# CPSW_CPSW_52800000h register map
Vendor: Texas Instruments
Registers are 32-bit, read-write, reset 0x0 unless marked. A register's access mark holds for its fields unless they carry their own. Offsets are as the file gives them; [hi:lo] are bit positions; {n}, {i} and the like mark numbered series; 'fields as' and 'values as' point back to an identical list.

## CPSW (part 3 of 4)
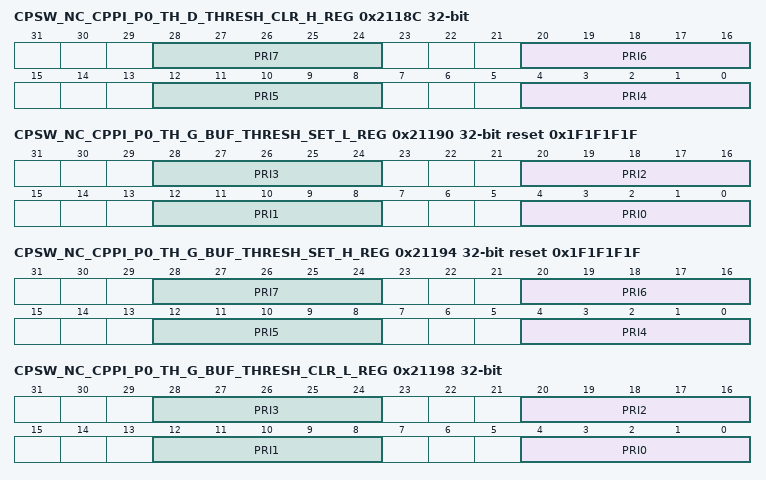
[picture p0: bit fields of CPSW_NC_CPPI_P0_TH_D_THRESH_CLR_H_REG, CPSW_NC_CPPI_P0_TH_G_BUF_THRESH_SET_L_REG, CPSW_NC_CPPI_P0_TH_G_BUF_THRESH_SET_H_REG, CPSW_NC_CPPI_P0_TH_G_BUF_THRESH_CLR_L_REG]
0x2118C CPSW_NC_CPPI_P0_TH_D_THRESH_CLR_H_REG — CPPI Port 0 Tx PFC Destination Threshold Clr High
  [8n-28:8n-32] PRI{n} (n=4..7) — Port Priority Based Flow Control Threshold Clear Value for Priority {n}
0x21190 CPSW_NC_CPPI_P0_TH_G_BUF_THRESH_SET_L_REG reset 0x1F1F1F1F — CPPI Port 0 Tx PFC Global Buffer Threshold Set Low
  [8n+4:8n] PRI{n} (n=0..3) — Port Priority Based Flow Control Threshold Set Value for Priority {n}
0x21194 CPSW_NC_CPPI_P0_TH_G_BUF_THRESH_SET_H_REG reset 0x1F1F1F1F — CPPI Port 0 Tx PFC Global Buffer Threshold Set High
  [8n-28:8n-32] PRI{n} (n=4..7) — Port Priority Based Flow Control Threshold Set Value for Priority {n}
0x21198 CPSW_NC_CPPI_P0_TH_G_BUF_THRESH_CLR_L_REG — CPPI Port 0 Tx PFC Global Buffer Threshold Clr Low
  [8n+4:8n] PRI{n} (n=0..3) — Port Priority Based Flow Control Threshold Clear Value for Priority {n}
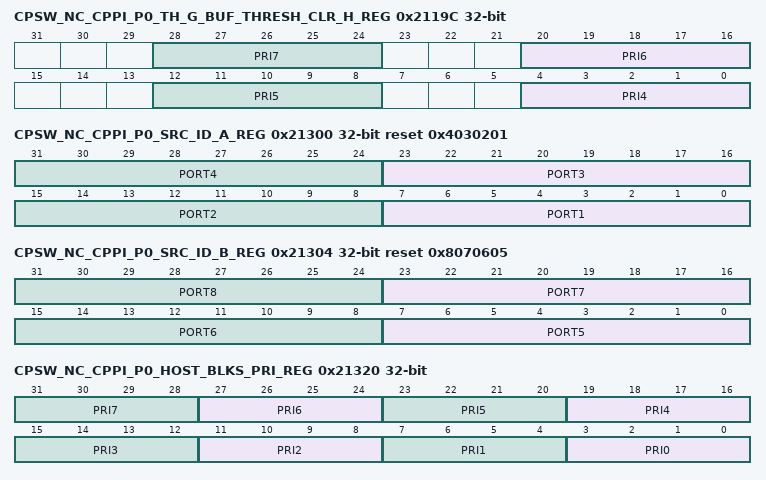
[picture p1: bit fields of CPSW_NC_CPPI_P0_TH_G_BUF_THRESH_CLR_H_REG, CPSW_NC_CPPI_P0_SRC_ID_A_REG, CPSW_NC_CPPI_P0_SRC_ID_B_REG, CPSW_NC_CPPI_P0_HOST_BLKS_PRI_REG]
0x2119C CPSW_NC_CPPI_P0_TH_G_BUF_THRESH_CLR_H_REG — CPPI Port 0 Tx PFC Global Buffer Threshold Clr High
  fields as CPSW_NC_CPPI_P0_TH_D_THRESH_CLR_H_REG
0x21300 CPSW_NC_CPPI_P0_SRC_ID_A_REG reset 0x4030201 — CPPI Port 0 CPPI Source ID A
  [8n-1:8n-8] PORT{n} (n=1..4) — Port {n} CPPI Info Word0 Source ID Value
0x21304 CPSW_NC_CPPI_P0_SRC_ID_B_REG reset 0x8070605 — CPPI Port 0 CPPI Source ID B
  [8n-33:8n-40] PORT{n} (n=5..8) — Port {n} CPPI Info Word0 Source ID Value
0x21320 CPSW_NC_CPPI_P0_HOST_BLKS_PRI_REG — CPPI Port 0 Host Blocks Priority
  [4n+3:4n] PRI{n} (n=0..7) — Priority {n} Host Blocks
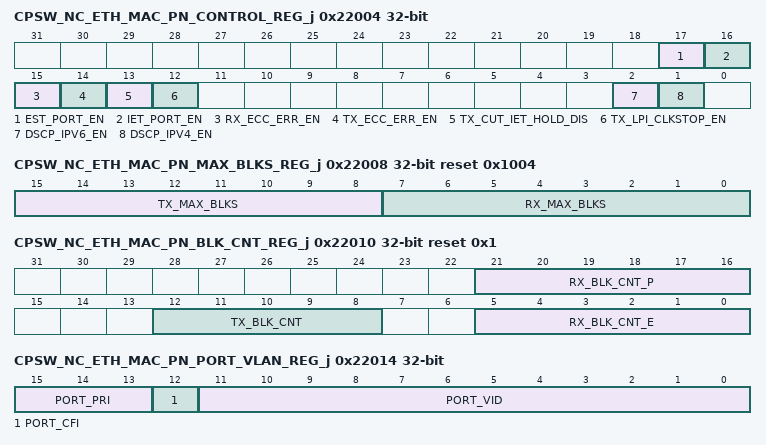
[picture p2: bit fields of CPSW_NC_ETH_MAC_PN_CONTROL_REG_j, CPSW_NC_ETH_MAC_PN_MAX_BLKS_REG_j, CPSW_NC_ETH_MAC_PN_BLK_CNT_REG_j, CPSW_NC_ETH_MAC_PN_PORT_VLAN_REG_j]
0x22004 CPSW_NC_ETH_MAC_PN_CONTROL_REG_j — Enet Port N Control
  [17] EST_PORT_EN — EST Port Enable 0 - EST is disabled on the port. 1 - EST is enabled on the port (Does not take effect until the CPSW level est_en is set).
  [16] IET_PORT_EN — IET Port Enable 0 - IET is disabled on the port 1 - IET is enabled on the port (Does not take effect until CPSW level iet_en is set).
  [15] RX_ECC_ERR_EN — This bit must be set to enable receive ECC error operations on the port.
  [14] TX_ECC_ERR_EN — This bit must be set to enable transmit ECC error operations on the port.
  [13] TX_CUT_IET_HOLD_DIS — Port N transmit IET hold due to cut-thru disable 0 - Cut-thru packets to the port will cause premptable traffic to be prempted as early as possible minimizing cut-thru latency. 1 - Cut-thru packets to the port will be prempted as usual by the express MAC. Included when iet_incl = 1 and cut_incl = 1.
  [12] TX_LPI_CLKSTOP_EN — Transmit LPI Clock Stop Enable - When set this bit causes the transmit output clock (GMII_GMTCLK_O) to be stopped when the transmit LPI state is entered if EEE is enabled.
  [2] DSCP_IPV6_EN — IPv6 DSCP enable 0 - Ipv6 DSCP priority mapping is disabled. 1 - Ipv6 DSCP priority mapping is enabled.
  [1] DSCP_IPV4_EN — IPv4 DSCP enable 0 - Ipv4 DSCP priority mapping is disabled. 1 - Ipv4 DSCP priority mapping is enabled.
0x22008 CPSW_NC_ETH_MAC_PN_MAX_BLKS_REG_j reset 0x1004 — Enet Port N FIFO Max Blocks
  [15:8] TX_MAX_BLKS — Transmit Max Blocks - The maximum number of blocks allowed on all transmit FIFO priorities combined. If (fifo_oneram = 1) then blocks should be moved from transmit to receive when flow control is enabled to allow for flow control runout.
  [7:0] RX_MAX_BLKS — Receive Max Blocks - The maximum number of blocks allowed on the express and prempt receive FIFOs (transmit and receive FIFOs combined when fifo_oneram = 1)
0x22010 CPSW_NC_ETH_MAC_PN_BLK_CNT_REG_j ro reset 0x1 — Enet Port N FIFO Block Usage Count
  [21:16] RX_BLK_CNT_P — Receive Express Block Count Usage - This value is the number of blocks allocated to the port FIFO prempt receive queue. No blocks are allocated until the iet_en in the CPSW_Control register is set.
  [12:8] TX_BLK_CNT — Transmit Block Count Usage - This value is the number of blocks allocated to the port FIFO logical transmit queues.
  [5:0] RX_BLK_CNT_E — Receive Express Block Count Usage - This value is the number of blocks allocated to the ports FIFO express receive queue.
0x22014 CPSW_NC_ETH_MAC_PN_PORT_VLAN_REG_j — Enet Port N VLAN
  [15:13] PORT_PRI — Port VLAN Priority
  [12] PORT_CFI — Port CFI bit
  [11:0] PORT_VID — Port VLAN ID
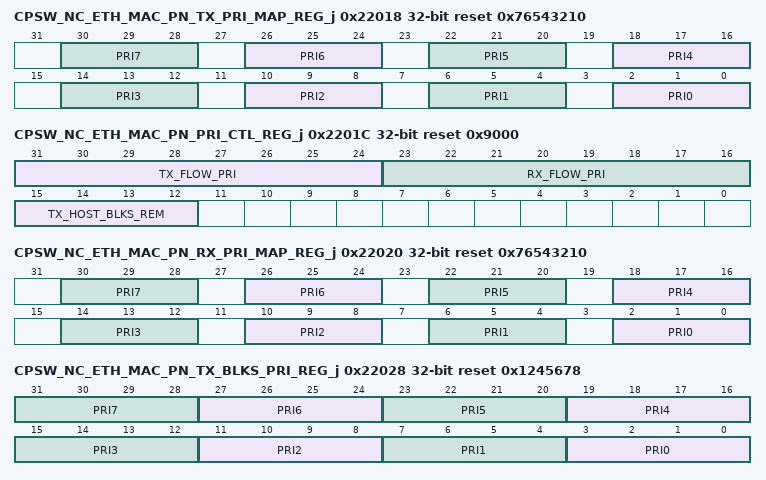
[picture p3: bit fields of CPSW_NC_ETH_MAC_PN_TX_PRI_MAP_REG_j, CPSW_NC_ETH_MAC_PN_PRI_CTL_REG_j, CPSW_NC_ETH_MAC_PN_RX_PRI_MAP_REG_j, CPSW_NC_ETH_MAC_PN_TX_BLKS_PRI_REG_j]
0x22018 CPSW_NC_ETH_MAC_PN_TX_PRI_MAP_REG_j reset 0x76543210 — Enet Port N Tx Header Pri to Switch Pri Mapping
  [4n+2:4n] PRI{n} (n=0..7) — Priority {n} - A packet header priority of {0x0+n} is given this switch queue priority.
0x2201C CPSW_NC_ETH_MAC_PN_PRI_CTL_REG_j reset 0x9000 — Enet Port N Priority Control
  [31:24] TX_FLOW_PRI — Transmit Priority Based Flow Control Enable (per priority)
  [23:16] RX_FLOW_PRI — Receive Priority Based Flow Control Enable (per priority)
  [15:12] TX_HOST_BLKS_REM — Transmit FIFO Blocks that must be free before a non rate-limited CPPI Port 0 receive thread can begin sending a packet
0x22020 CPSW_NC_ETH_MAC_PN_RX_PRI_MAP_REG_j reset 0x76543210 — Enet Port N RX Pkt Pri to Header Pri Map
  [4n+2:4n] PRI{n} (n=0..7) — Priority {n} - A packet priority of {n} is mapped (changed) to this header packet priority.
0x22024 CPSW_NC_ETH_MAC_PN_RX_MAXLEN_REG_j reset 0x5EE — Enet Port N Receive Frame Max Length
  [13:0] RX_MAXLEN — RX Maximum Frame Length - This field determines the maximum length of a received frame. The reset value is 1518 (dec). Frames with byte counts greater than pn_rx_maxlen are long frames. Long frames with no errors are oversized frames. Long frames with CRC, code, or alignment error are jabber frames. The maximum value is 2024 (including VLAN).
0x22028 CPSW_NC_ETH_MAC_PN_TX_BLKS_PRI_REG_j reset 0x1245678 — Enet Port N Transmit Block Sub Per Priority
  [4n+3:4n] PRI{n} (n=0..7) — Transmit Blocks Per Priority {n} (subtract value)
0x22030 CPSW_NC_ETH_MAC_PN_IDLE2LPI_REG_j — Enet Port N EEE Idle to LPI counter
  [23:0] COUNT — EEE Idle to LPI counter load value - After CLKSTOP_REQ is asserted, this value is loaded into the port idle to LPI counter on each clock that the port transmit is not idle. The port enters the transmit LPI state when this counter decrements to zero. This counter decrements each time the EEE prescale counter decrements to zero.
0x22034 CPSW_NC_ETH_MAC_PN_LPI2WAKE_REG_j — Enet Port N EEE LPI to wake counter
  [23:0] COUNT — EEE LPI to wake counter load value - When the port is in the transmit LPI state and the CLKSTOP_REQ signal is deasserted, this value is loaded into the LPI to wake counter. Transmit packet operations may begin (resume) when the LPI to wake count decrements to zero (on the pre-scale count). This is the time that the transmit must wait before transmit packet operations resume after wakeup.
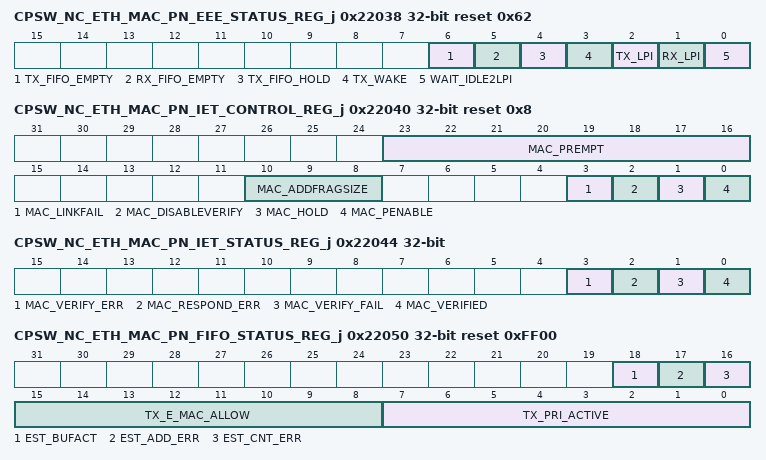
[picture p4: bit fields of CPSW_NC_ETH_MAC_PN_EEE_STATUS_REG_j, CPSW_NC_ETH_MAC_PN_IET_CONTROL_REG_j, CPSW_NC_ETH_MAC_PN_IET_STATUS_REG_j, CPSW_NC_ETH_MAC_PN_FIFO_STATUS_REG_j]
0x22038 CPSW_NC_ETH_MAC_PN_EEE_STATUS_REG_j ro reset 0x62 — Enet Port N EEE status
  [6] TX_FIFO_EMPTY — Transmit FIFO (switch egress) is empty - contains no packets
  [5] RX_FIFO_EMPTY — Receive FIFO (switch ingress) is empty - contains no packets
  [4] TX_FIFO_HOLD — Transmit FIFO hold - asserted in the LPI state and during the LPI2WAKE count time
  [3] TX_WAKE — Transmit wakeup - asserted in the transmit LPI2WAKE count time
  [2] TX_LPI — Transmit LPI state - asserted when the port 0 transmit is in the LPI state
  [1] RX_LPI — Receive LPI state - asserted when the port 0 receive is in the LPI state
  [0] WAIT_IDLE2LPI — CPPI port 0 wait idle to LPI - asserted when port 0 is counting the IDLE2LPI time
0x22040 CPSW_NC_ETH_MAC_PN_IET_CONTROL_REG_j reset 0x8 — Enet Port N IET Control
  [23:16] MAC_PREMPT — Mac Prempt Queue - Indicates which transmit FIFO queues are sent to the prempt MAC. Bit 0 indicates queue zero, bit 1 queue 1 and so on. Packets will be sent to the prempt MAC only when pn_mac_penable is set, and when mac_verified (from Enet_Pn_IET_Status) or pn_mac_disableverify is set, and when pn_iet_port_en is set.
  [10:8] MAC_ADDFRAGSIZE — Mac Fragment Size - An integer in the range 0 to 7 indicating, as a multiple of 64, the minimum additional length for nonfinal mPackets 0 = 64 1 = 128 ... 7 = 512
  [3] MAC_LINKFAIL — Mac Link Fail - Link Fail Indicatior to reset the verifly state machine. This bit is high on reset. Verify and response frames will be sent/allowed when this bit is cleared.
  [2] MAC_DISABLEVERIFY — Mac Disable Verify - Disables verification on the port when set. If this bit is set then packets will be sent to the prempt MAC when mac_penable is set (This is a forced mode with no IET verification).
  [1] MAC_HOLD — Mac Hold - Hold Premption on the port when set.
  [0] MAC_PENABLE — Mac Premption Enable - Port Premption Enable. This takes effect only when pn_iet_port_en is set.
0x22044 CPSW_NC_ETH_MAC_PN_IET_STATUS_REG_j ro — Enet Port N IET Status
  [3] MAC_VERIFY_ERR — Mac Received Verify Packet with Errors - Set when a verify packet with errors is received. Cleared when pn_mac_penable is cleared to zero.
  [2] MAC_RESPOND_ERR — Mac Received Respond Packet with Errors - Set when a respond packet with errors is received. Cleared when pn_mac_penable is cleared to zero.
  [1] MAC_VERIFY_FAIL — Mac Verification Failed - Indication that verification was unsuccessful
  [0] MAC_VERIFIED — Mac Verified - Indication that verification was successful.
0x22048 CPSW_NC_ETH_MAC_PN_IET_VERIFY_REG_j reset 0x1312D0 — Enet Port N IET VERIFY
  [23:0] MAC_VERIFY_CNT — Mac Verify Timeout Count - The number of wireside clocks contained in the verify timeout counter. The default is 0x1312d0 (10ms at 125Mhz in gig mode)
0x22050 CPSW_NC_ETH_MAC_PN_FIFO_STATUS_REG_j ro reset 0xFF00 — Enet Port N FIFO STATUS
  [18] EST_BUFACT — EST RAM active buffer - Indicates the active 64-word fetch buffer when pn_est_onebuf is cleared to zero. Indicates the fetch ram address MSB when pn_est_onebuf set to one.
  [17] EST_ADD_ERR — EST Address Error - Indicates that the fetch ram was read again after the previous maximum buffer address read (the previous fetch from the maximum address is reused).
  [16] EST_CNT_ERR — EST Fetch Count Error - Indicates that insufficient clocks were programmed into the fetch count and that another fetch was commanded before the previous fetch finished.
  [15:8] TX_E_MAC_ALLOW — Transmit mac allow - Bus that indicates the actual priorities assigned to the express queue (and inversely the priorities assigned to the prempt queue). The pn_mac_prempt[7:0] field in the Enet_Pn_IET_Control register indicates which priorities should be assigned to the express/prempt queues. The switch between queues happens only when the priority is empty and the actual assignment is shown in this field.
  [7:0] TX_PRI_ACTIVE — Transmit Priority Active - Bus that indicates which priorities have packets (non-empty) at the time of the register read.
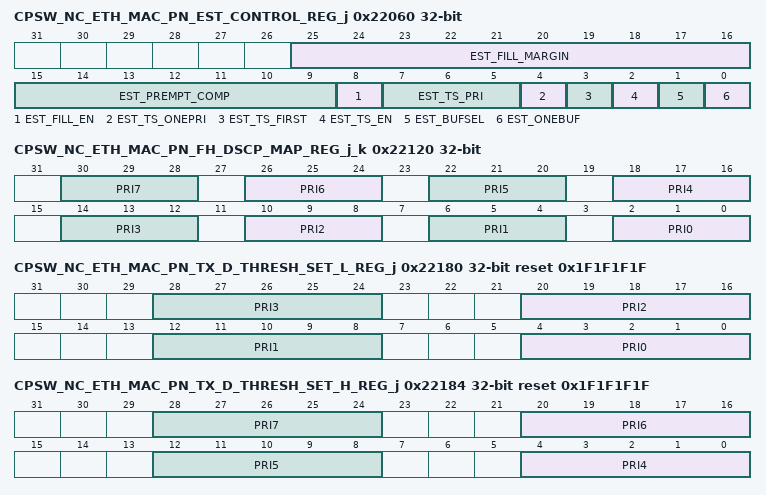
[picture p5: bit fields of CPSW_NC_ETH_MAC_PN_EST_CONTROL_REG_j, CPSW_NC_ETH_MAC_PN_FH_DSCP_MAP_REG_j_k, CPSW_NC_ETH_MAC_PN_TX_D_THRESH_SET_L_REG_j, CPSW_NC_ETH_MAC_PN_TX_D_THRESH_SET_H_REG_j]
0x22060 CPSW_NC_ETH_MAC_PN_EST_CONTROL_REG_j — Enet Port N EST CONTROL
  [25:16] EST_FILL_MARGIN — EST Fill Margin - Sets the fill margin (in bytes) required to ensure that the Ethernet wire is clear so that the timed EST express packet can egress at the correct required time. Setting this value too high will put an unnecessary gap on the wire. Setting this value too low will cause the express packet to egress at a time later than intended (pushed out by non express traffic that did not have sufficient time to finish).
  [15:9] EST_PREMPT_COMP — EST Prempt Comparison Value - When the count in a zero allow is less than or equal to this value in bytes (times 8), prempt packets are cleared from the wire. This is the prempt clear margin value.
  [8] EST_FILL_EN — EST Fill Enable - Enable EST fill mode when set.
  [7:5] EST_TS_PRI — EST Timestamp Express Priority - Selects the express priority that timestamp(s) will be generated on when pn_est_ts_onepri is set.
  [4] EST_TS_ONEPRI — EST Timestamp One Express Priority - When set, timestamps are only enabled on packets on the express priority selected by pn_est_ts_pri. When cleared to zero, express packet selection for timestamps is independent of priority.
  [3] EST_TS_FIRST — EST Timestamp First Express Packet only - Generate a timestamp only on the first selected express packet in each EST time interval when express timestamps are enabled. (If pn_est_ts_onepri is also set then the timestamp is generated only on the first packet on pn_est_ts_pri).
  [2] EST_TS_EN — EST Timestamp Enable - Enable express timestamps (when est_en and pn_est_port_en are set).
  [1] EST_BUFSEL — EST Buffer Select - If pn_est_onebuf is cleared, this bit selects the upper (when set) or the lower (when cleared) 64-word fetch buffer. The actual fetch buffer used changes only at the start of the EST time interval and can be read in the Enet_Pn_FIFO_Status register pn_est_bufact bit.
  [0] EST_ONEBUF — EST One Fetch Buffer - When set indicates that all 128 fetch words are used in one buffer. When cleared, indicates that the 128 fetch words are split into two 64-word fetch buffers. The pn_est_bufsel selects the buffer to be used when pn_est_onebuf is cleared to zero. Two buffers allows software to change a buffer while the hardware is using the other buffer.
0x22120 CPSW_NC_ETH_MAC_PN_FH_DSCP_MAP_REG_j_k — Enet Port N Receive IPV4/IPV6 DSCP Map N
  [4n+2:4n] PRI{n} (n=0..7) — A DSCP IPV4/V6 packet TOS {n} is mapped to this received priority
0x22140 CPSW_NC_ETH_MAC_PN_PRI_CIR_REG_j_k — Enet Port N Rx Priority P Committed Information Rate Value
  [27:0] PRI_CIR — Priority N committed information rate
0x22160 CPSW_NC_ETH_MAC_PN_PRI_EIR_REG_j_k — Enet Port N Rx Priority P Excess Informatoin Rate Value
  [27:0] PRI_EIR — Priority N Excess Information Rate count
0x22180 CPSW_NC_ETH_MAC_PN_TX_D_THRESH_SET_L_REG_j reset 0x1F1F1F1F — Enet Port N Tx PFC Destination Threshold Set Low
  fields as CPSW_NC_CPPI_P0_TH_G_BUF_THRESH_SET_L_REG
0x22184 CPSW_NC_ETH_MAC_PN_TX_D_THRESH_SET_H_REG_j reset 0x1F1F1F1F — Enet Port N Tx PFC Destination Threshold Set High
  fields as CPSW_NC_CPPI_P0_TH_G_BUF_THRESH_SET_H_REG
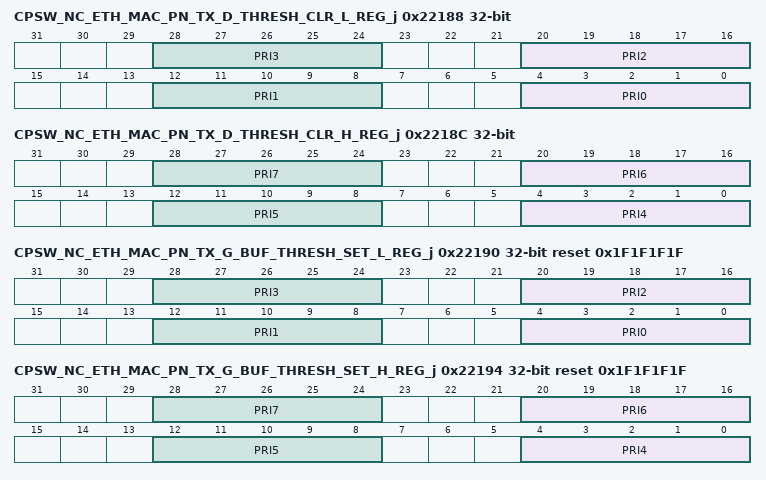
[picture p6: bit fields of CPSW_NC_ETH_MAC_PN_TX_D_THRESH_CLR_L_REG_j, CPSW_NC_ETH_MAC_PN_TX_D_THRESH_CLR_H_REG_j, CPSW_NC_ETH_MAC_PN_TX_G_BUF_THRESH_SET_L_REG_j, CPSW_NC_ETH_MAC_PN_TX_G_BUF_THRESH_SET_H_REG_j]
0x22188 CPSW_NC_ETH_MAC_PN_TX_D_THRESH_CLR_L_REG_j — Enet Port N Tx PFC Destination Threshold Clr Low
  fields as CPSW_NC_CPPI_P0_TH_G_BUF_THRESH_CLR_L_REG
0x2218C CPSW_NC_ETH_MAC_PN_TX_D_THRESH_CLR_H_REG_j — Enet Port N Tx PFC Destination Threshold Clr High
  fields as CPSW_NC_CPPI_P0_TH_D_THRESH_CLR_H_REG
0x22190 CPSW_NC_ETH_MAC_PN_TX_G_BUF_THRESH_SET_L_REG_j reset 0x1F1F1F1F — Enet Port N Tx PFC Global Buffer Threshold Set Low
  fields as CPSW_NC_CPPI_P0_TH_G_BUF_THRESH_SET_L_REG
0x22194 CPSW_NC_ETH_MAC_PN_TX_G_BUF_THRESH_SET_H_REG_j reset 0x1F1F1F1F — Enet Port N Tx PFC Global Buffer Threshold Set High
  fields as CPSW_NC_CPPI_P0_TH_G_BUF_THRESH_SET_H_REG
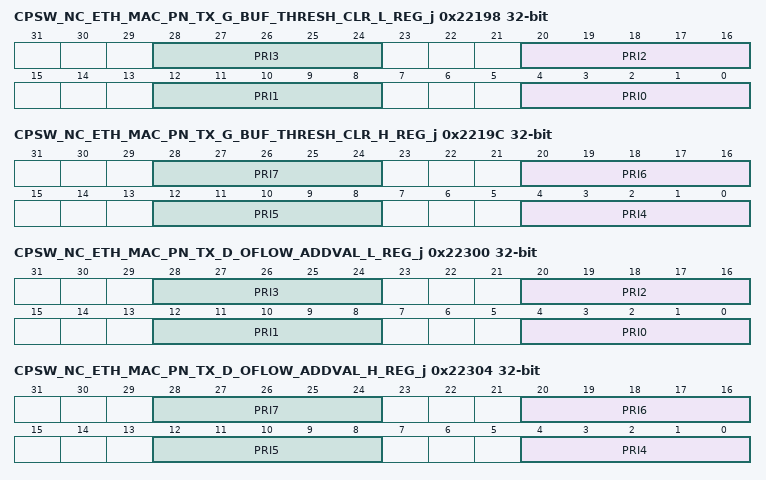
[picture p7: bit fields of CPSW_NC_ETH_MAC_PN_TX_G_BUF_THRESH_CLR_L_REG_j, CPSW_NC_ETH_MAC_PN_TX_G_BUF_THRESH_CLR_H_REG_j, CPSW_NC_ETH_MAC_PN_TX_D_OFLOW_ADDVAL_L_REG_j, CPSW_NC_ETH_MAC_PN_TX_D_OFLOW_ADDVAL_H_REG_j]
0x22198 CPSW_NC_ETH_MAC_PN_TX_G_BUF_THRESH_CLR_L_REG_j — Enet Port N Tx PFC Global Buffer Threshold Clr Low
  fields as CPSW_NC_CPPI_P0_TH_G_BUF_THRESH_CLR_L_REG
0x2219C CPSW_NC_ETH_MAC_PN_TX_G_BUF_THRESH_CLR_H_REG_j — Enet Port N Tx PFC Global Buffer Threshold Clr High
  fields as CPSW_NC_CPPI_P0_TH_D_THRESH_CLR_H_REG
0x22300 CPSW_NC_ETH_MAC_PN_TX_D_OFLOW_ADDVAL_L_REG_j — Enet Port N Tx Destination Out Flow Add Values Low
  [8n+4:8n] PRI{n} (n=0..3) — Port PFC Destination Based Out Flow Add Value for Priority {n}
0x22304 CPSW_NC_ETH_MAC_PN_TX_D_OFLOW_ADDVAL_H_REG_j — Enet Port N Tx Destination Out Flow Add Values High
  [8n-28:8n-32] PRI{n} (n=4..7) — Port PFC Destination Based Out Flow Add Value for Priority {n}
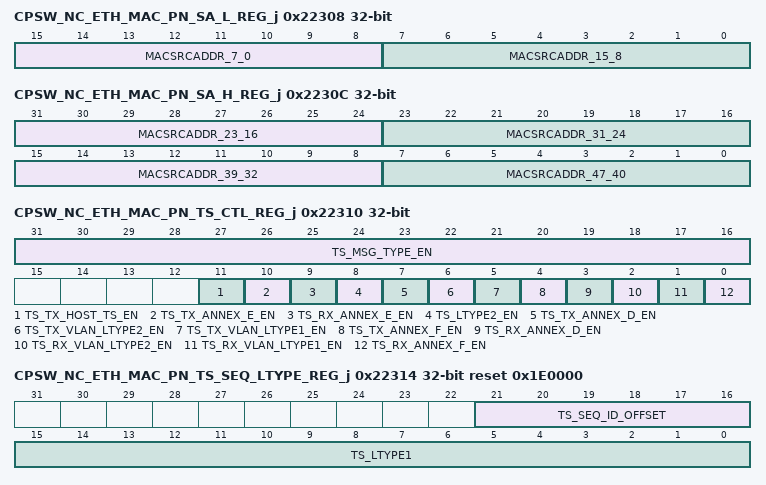
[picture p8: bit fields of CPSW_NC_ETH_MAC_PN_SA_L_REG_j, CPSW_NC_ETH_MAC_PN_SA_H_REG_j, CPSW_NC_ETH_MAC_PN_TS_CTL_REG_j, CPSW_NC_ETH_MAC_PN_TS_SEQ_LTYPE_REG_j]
0x22308 CPSW_NC_ETH_MAC_PN_SA_L_REG_j — Enet Port N Tx Pause Frame Source Address Low
  [15:8] MACSRCADDR_7_0 — Source Address bits 7:0
  [7:0] MACSRCADDR_15_8 — Source Address bits 15:8
0x2230C CPSW_NC_ETH_MAC_PN_SA_H_REG_j — Enet Port N Tx Pause Frame Source Address High
  [31:24] MACSRCADDR_23_16 — Source Address bits 23:16
  [23:16] MACSRCADDR_31_24 — Source Address bits 31:24
  [15:8] MACSRCADDR_39_32 — Source Address bits 39:32
  [7:0] MACSRCADDR_47_40 — Source Address bits 47:40
0x22310 CPSW_NC_ETH_MAC_PN_TS_CTL_REG_j — Enet Port N Time Sync Control
  [31:16] TS_MSG_TYPE_EN — Time Sync Message Type Enable - Each bit in this field enables the corresponding message type in receive and transmit time sync messages (Bit 0 enables message type 0 etc.)
  [11] TS_TX_HOST_TS_EN — Time Sync Transmit Host Time Stamp Enable
  [10] TS_TX_ANNEX_E_EN — Time Synce Transmit Annex E Enable
  [9] TS_RX_ANNEX_E_EN — Time Synce Receive Annex E Enable
  [8] TS_LTYPE2_EN — Time Sync LTYPE 2 Enable (transmit and receive)
  [7] TS_TX_ANNEX_D_EN — Time Synce Transmit Annex D Enable
  [6] TS_TX_VLAN_LTYPE2_EN — Time Sync Transmit VLAN LTYPE 2 enable
  [5] TS_TX_VLAN_LTYPE1_EN — Time Sync Transmit VLAN LTYPE 1 enable
  [4] TS_TX_ANNEX_F_EN — Time Synce Transmit Annex F Enable
  [3] TS_RX_ANNEX_D_EN — Time Synce Receive Annex D Enable
  [2] TS_RX_VLAN_LTYPE2_EN — Time Sync Receive VLAN LTYPE 2 enable
  [1] TS_RX_VLAN_LTYPE1_EN — Time Sync Receive VLAN LTYPE 1 enable
  [0] TS_RX_ANNEX_F_EN — Time Synce Receive Annex F Enable
0x22314 CPSW_NC_ETH_MAC_PN_TS_SEQ_LTYPE_REG_j reset 0x1E0000 — Enet Port N Time Sync LTYPE (and SEQ_ID_OFFSET)
  [21:16] TS_SEQ_ID_OFFSET — Time Sync Sequence ID Offset - This is the number of octets that the sequence ID is offset in the tx and rx time sync message header. The minimum value is 6.
  [15:0] TS_LTYPE1 — Time Sync LTYPE1 - This is the port time sync LTYPE1 value
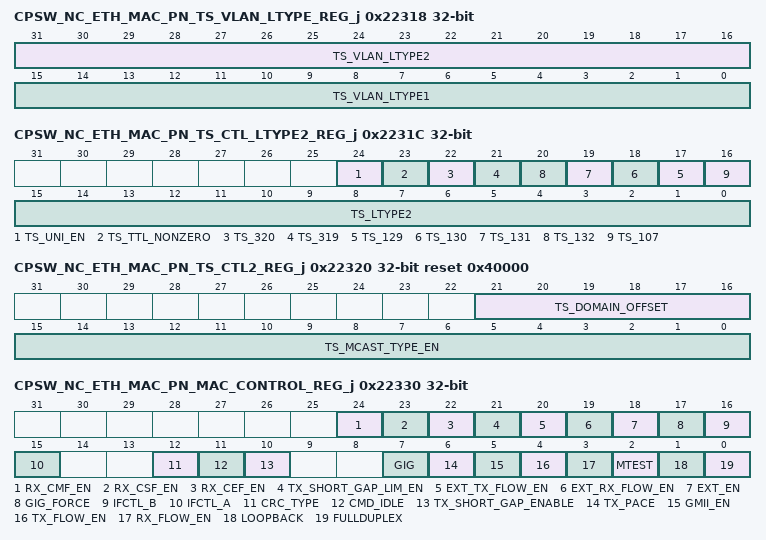
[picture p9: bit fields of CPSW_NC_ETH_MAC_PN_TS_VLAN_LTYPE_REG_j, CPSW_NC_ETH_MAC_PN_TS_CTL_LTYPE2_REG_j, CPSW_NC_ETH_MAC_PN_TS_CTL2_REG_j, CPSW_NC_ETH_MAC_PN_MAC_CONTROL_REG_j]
0x22318 CPSW_NC_ETH_MAC_PN_TS_VLAN_LTYPE_REG_j — Enet Port N Time Sync VLAN2 and VLAN2
  [31:16] TS_VLAN_LTYPE2 — Time Sync VLAN LTYPE2
  [15:0] TS_VLAN_LTYPE1 — Time Sync VLAN LTYPE1
0x2231C CPSW_NC_ETH_MAC_PN_TS_CTL_LTYPE2_REG_j — Enet Port N Time Sync Control and LTYPE 2
  [24] TS_UNI_EN — Time Sync Unicast Enable
  [23] TS_TTL_NONZERO — Time Sync Time to Live Non-zero Enable
  [22] TS_320 — Time Sync Destination Port Number 320 Enable
  [21] TS_319 — Time Sync Destination Port Number 319 Enable
  [n-112] TS_{n} (n=129..132) — Time Sync Destination IP Address {n} Enable
  [16] TS_107 — Time Sync Destination IP Address 107 Enable
  [15:0] TS_LTYPE2 — Time Sync LTYPE2 value
0x22320 CPSW_NC_ETH_MAC_PN_TS_CTL2_REG_j reset 0x40000 — Enet Port N Time Sync Control 2
  [21:16] TS_DOMAIN_OFFSET — Time Sync Domain Offset
  [15:0] TS_MCAST_TYPE_EN — Time Sync Multicast Destination Address Type Enable
0x22330 CPSW_NC_ETH_MAC_PN_MAC_CONTROL_REG_j — Enet Port N Mac Control
  [24] RX_CMF_EN — RX Copy MAC Control Frames Enable - Enables MAC control frames to be transferred to memory. MAC control frames are normally acted upon (if enabled), but not copied/transferred to memory. MAC control frames that are pause frames will be acted upon if enabled in the MacControl register, regardless of the value of pn_rx_cmf_en. Frames transferred to memory due to pn_rx_cmf_en will have the mac_control bit set in their EOP buffer descriptor. 0 - MAC control frames are filtered (but are acted upon if enabled). 1 - MAC control frames are transferred to the host.
  [23] RX_CSF_EN — RX Copy Short Frames Enable - Enables frames or fragments shorter than 64 bytes to be sent to the host. Frames transferred to the host due to pn_rx_csf_en will have the fragment or undersized bit set in their buffer descriptor. Short and fragment frame transfer is not guaranteed for all packet conditions and is best case only. Frames shorter than 33 bytes will be dropped in all cases. Fragments are short frames that contain CRC/align/code errors and undersized are short frames without errors. The pn_rx_cef_en bit must also be set to transfer fragment frames. 0 - Short frames are filtered. 1 - Short frames are transferred to the host.
  [22] RX_CEF_EN — RX Copy Error Frames Enable - Enables frames containing errors to be transferred to memory. The appropriate error bit will be set in the frame receive buffer descriptor. Frames containing errors will be filtered when this bit is not set. 0 - Frames containing errors are filtered. 1 - Frames containing errors are transferred to the host.
  [21] TX_SHORT_GAP_LIM_EN — Transmit Short Gap Limit Enable - When set this bit limits the number of short gap packets transmitted to 100ppm. The pn_tx_short_gap_en bit must also be set. Each time a short gap packet is sent, a counter is loaded with 10,000 and decremented on each wireside clock. Another short gap packet will not be sent out until the counter decrements to zero. This mode is included to preclude the host from filling up the FIFO and sending every packet out with short gap which would violate the maximum number of packets per second allowed. This bit is used only with GMII (not XGMII).
  [20] EXT_TX_FLOW_EN — External Transmit Flow Control Enable - Enables the pn_tx_flow_en to be selected from the EXT_TX_FLOW_EN input signal and not from the pn_tx_flow_en bit in this register.
  [19] EXT_RX_FLOW_EN — External Receive Flow Control Enable - Enables the pn_rx_flow_en to be selected from the EXT_RX_FLOW_EN input signal and not from the pn_rx_flow_en bit in this register.
  [18] EXT_EN — External Control Enable - Enables the fullduplex and gigabit mode to be selected from the FULLDUPLEX_IN and GIG_IN input signals and not from the pn_fullduplex and pn_gig bits in this register. The FULLDUPLEX_MODE bit reflects the actual fullduplex mode selected.
  [17] GIG_FORCE — Gigabit Mode Force - This bit is used to force the Enet Mac into gigabit mode if the input GMII_MTCLK has been stopped by the PHY. 0 - GIG mode not forced 1 - GIG mode forced regardless of transmit clock
  [16] IFCTL_B — Interface Control B - Intended as a general purpose output bit to be used to control external gaskets associated with the GMII (GMII to RGMII etc).
  [15] IFCTL_A — Interface Control A - Intended as a general purpose output bit to be used to control external gaskets associated with the GMII (GMII to RGMII etc).
  [12] CRC_TYPE — Port CRC Type - 0 - Ethernet CRC. 1 - Castagnoli CRC.
  [11] CMD_IDLE — Command Idle - 0 - Idle not commanded. 1 - Idle Commanded (read pn_idle in Enet_Pn_Mac_Status).
  [10] TX_SHORT_GAP_ENABLE — Transmit Short Gap Enable 0 - Transmit with a short IPG is disabled. 1 - Transmit with a short IPG is enabled.
  [7] GIG — Gigabit Mode - 0 - 10/100 mode. 1 - Gigabit mode (full duplex only) The GIG_OUT output is the value of this bit. This bit is a don't care when pn_xgig is set.
  [6] TX_PACE — Transmit Pacing Enable - 0 - Transmit Pacing Disabled. 1 - Transmit Pacing Enabled
  [5] GMII_EN — GMII Enable - 0 - GMII RX and TX held in reset. 1 - GMII RX and TX released from reset. This bit should be written with a logic high before the other bits in this register are written.
  [4] TX_FLOW_EN — Transmit Flow Control Enable - Determines if incoming pause frames are acted upon in full-duplex mode. Incoming pause frames are not acted upon in half-duplex mode regardless of this bit setting. The RX_MBP_Enable bits determine whether or not received pause frames are transferred to memory. 0 - Transmit Flow Control Disabled. Full-duplex mode - Incoming pause frames are not acted upon. 1 - Transmit Flow Control Enabled . Full-duplex mode - Incoming pause frames are acted upon.
  [3] RX_FLOW_EN — Receive Flow Control Enable - 0 - Receive Flow Control Disabled: Half-duplex mode - No flow control generated collisions are sent. Full-duplex mode - No outgoing pause frames are sent. 1 - Receive Flow Control Enabled: Half-duplex mode - Collisions are initiated when receive flow control is triggered. Full-duplex mode - Outgoing pause frames are sent when receive flow control is triggered.
  [2] MTEST — Manufacturing Test mode - This bit must be set to allow writes to the Backoff_Test and PauseTimer registers.
  [1] LOOPBACK — Loop Back Mode - Loopback mode forces internal fullduplex mode regardless of whether the pn_fullduplex bit is set or not. The pn_loopback bit should be changed only when pn_gmii_en is de-asserted. Loopback is used only with GMII (not XGMII). Loopback is not compatible with timestamp operations (CPTS). 0 - Loop Back Mode disabled. 1 - Loop Back Mode enabled.
  [0] FULLDUPLEX — Full Duplex mode - Gigabit mode forces fullduplex mode regardless of whether the pn_fullduplex bit is set or not. The FULLDUPLEX_OUT output is the value of this register bit. 0 - half duplex mode. 1 - full duplex mode.
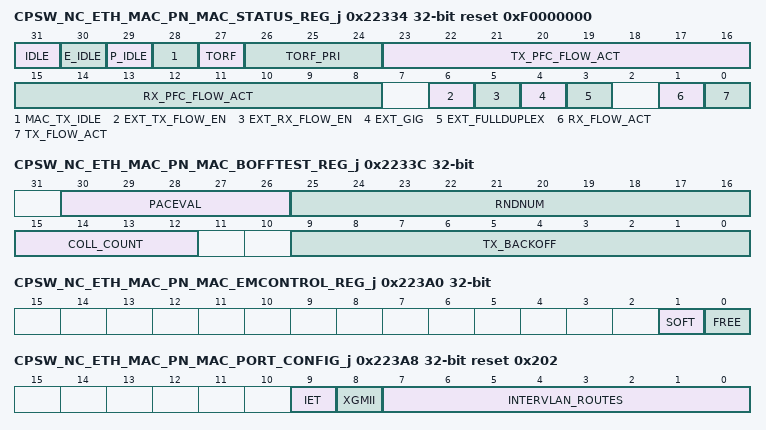
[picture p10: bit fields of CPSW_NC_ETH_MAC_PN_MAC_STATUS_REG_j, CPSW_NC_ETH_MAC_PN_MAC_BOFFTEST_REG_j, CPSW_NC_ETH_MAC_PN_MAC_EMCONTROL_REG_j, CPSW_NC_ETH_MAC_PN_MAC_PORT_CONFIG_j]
0x22334 CPSW_NC_ETH_MAC_PN_MAC_STATUS_REG_j ro reset 0xF0000000 — Enet Port N Mac Status
  [31] IDLE — Enet IDLE - The Ethernet port (express and prempt) is in the idle state when high.
  [30] E_IDLE — Express MAC is idle when high
  [29] P_IDLE — Prempt MAC is idle when high
  [28] MAC_TX_IDLE — Mac Transmit Idle - Both Prempt (if iet_incl) and Express MAC Transmit are in idle state.The transmit clock must be running for this to go idle.
  [27] TORF — Top of receive FIFO flow control trigger occurred. This bit is write one to clear.
  [26:24] TORF_PRI — The lowest priority that caused top of receive FIFO flow control trigger since the last write to clear. This field is write 0x7 to clear.
  [23:16] TX_PFC_FLOW_ACT — Receive Priority Based Flow Control Active (priority 7 down to 0).
  [15:8] RX_PFC_FLOW_ACT — Transmit Priority Based Flow Control Active (priority 7 down to 0).
  [6] EXT_TX_FLOW_EN — External Transmit Flow Control Enable - This is the value of the EXT_TX_FLOW_EN input bit.
  [5] EXT_RX_FLOW_EN — External Receive Flow Control Enable - This is the value of the EXT_RX_FLOW_EN input bit.
  [4] EXT_GIG — External GIG - This is the value of the EXT_GIG input bit.
  [3] EXT_FULLDUPLEX — External Fullduplex - This is the value of the EXT_FULLDUPLEX input bit.
  [1] RX_FLOW_ACT — Receive Flow Control Active - When asserted, indicates that receive flow control is enabled and triggered.
  [0] TX_FLOW_ACT — Transmit Flow Control Active - When asserted, this bit indicates that the pause time period is being observed for a received pause frame. No new transmissions will begin while this bit is asserted except for the transmission of pause frames. Any transmission in progress when this bit is asserted will complete.
0x22338 CPSW_NC_ETH_MAC_PN_MAC_SOFT_RESET_REG_j — Enet Port N Mac Soft Reset
  [0] SOFT_RESET — Software reset
0x2233C CPSW_NC_ETH_MAC_PN_MAC_BOFFTEST_REG_j access per field — Enet Port N Mac Backoff Test
  [30:26] PACEVAL rw — Pacing Current Value - A non-zero value in this field indicates that transmit pacing is active. A transmit frame collision or deferral causes paceval to loaded with decimal 31, good frame transmissions (with no collisions or deferrals) cause paceval to be decremented down to zero. When paceval is nonzero, the transmitter delays 4 IPGs between new frame transmissions after each successfully transmitted frame that had no deferrals or collisions. Transmit pacing helps reduce capture effects improving overall network bandwidth.
  [25:16] RNDNUM rw — Backoff Random Number Generator - This field allows the Backoff Random Number Generator to be read (or written in test mode only). This field can be written only when pn_mtest has previously been set. Reading this field returns the generator's current value. The value is reset to zero and begins counting on the clock after the de-assertion of reset.
  [15:12] COLL_COUNT ro — Collision Count - The number of collisions the current frame has experienced.
  [9:0] TX_BACKOFF ro — Backoff Count - This field allows the current value of the backoff counter to be observed for test purposes. This field is loaded automatically according to the backoff algorithm, and is decremented by one for each slot time after the collision.
0x22340 CPSW_NC_ETH_MAC_PN_MAC_RX_PAUSETIMER_REG_j — Enet Port N 802.3 Receive Pause Timer
  [15:0] RX_PAUSETIMER — RX Pause Timer Value - This field allows the contents of the receive pause timer to be observed (and written in test mode). The receive pause timer is loaded with 0xFF00 when the Enet port sends an outgoing pause frame (with pause time of 0xFFFF). The receive pause timer is decremented at slot time intervals. If the receive pause timer decrements to zero, then another outgoing pause frame will be sent and the load/decrement process will be repeated. This register is for 802.3 Based flow control and is not used for 802.1Qbb Priority Based Flow Control (PFC).
0x22350 CPSW_NC_ETH_MAC_PN_MAC_RXN_PAUSETIMER_REG_j_k — Enet Port N PFC Priority 0 Rx Pause Timer
  [15:0] RX0_PAUSETIMER — Rx N Pause Timer Value - This field allows the contents of the receive pause timer to be observed (and written in test mode). The receive pause timer is loaded with 0xFF00 when the Enet port sends an outgoing pause frame (with pause time of 0xFFFF). The receive pause timer is decremented at slot time intervals. If the receive pause timer decrements to zero, then another outgoing pause frame will be sent and the load/decrement process will be repeated. This register is for 802.1qbb Priority Based flow control (PFC)
0x22370 CPSW_NC_ETH_MAC_PN_MAC_TX_PAUSETIMER_REG_j — Enet Port N 802.3 Tx Pause Timer
  [15:0] TX_PAUSETIMER — 802.3 Tx Pause Timer Value - This field allows the contents of the transmit pause timer to be observed (and written in test mode). The transmit pause timer is loaded by a received (incoming) pause frame, and then decremented, at slottime intervals, down to zero at which time Ethernet Port transmit frames are again enabled. This register is for 802.3 Based flow control and is not used for 802.1qbb Priority Based Flow Control (PFC).
0x22380 CPSW_NC_ETH_MAC_PN_MAC_TX0_PAUSETIMER_REG_j_k — Enet Port N PFC Priority 0 Tx Pause Timer
  [15:0] TX0_PAUSETIMER — PFC Tx N Pause Timer Value - This field allows the contents of the transmit pause timer to be observed (and written in test mode). The transmit pause timer is loaded by a received (incoming) pause frame, and then decremented, at slottime intervals, down to zero at which time Ethernet Port transmit frames are again enabled. This register is for 802.1qbb Priority Based flow control (PFC)
0x223A0 CPSW_NC_ETH_MAC_PN_MAC_EMCONTROL_REG_j — Enet Port N Emulation Control
  [1] SOFT — Emulation Soft Bit
  [0] FREE — Emulation Free Bit
0x223A4 CPSW_NC_ETH_MAC_PN_MAC_TX_GAP_REG_j reset 0xC — Enet Port N Tx Inter Packet Gap
  [15:0] TX_GAP — Transmit Inter-Packet Gap - GMII modes - This is the default gap value and only bits 8:0 are used. This can be increased from 12 to increase the gap between packets. XGMII mode - In 10 gigabit mode this is the short gap rate and should be changed to 5000 (0x1388) to get approximately 200ppm faster when short gap is triggered and enabled.
0x223A8 CPSW_NC_ETH_MAC_PN_MAC_PORT_CONFIG_j ro reset 0x202 — Enet Port N Port Configuration
  [9] IET — IET support
  [8] XGMII — No XGMII support on this port
  [7:0] INTERVLAN_ROUTES — The number of InterVLAN routes supported on this port (egress)
0x223AC CPSW_NC_ETH_MAC_PN_INTERVLAN_OPX_POINTER_REG_j — Enet Port N Tx Egress InterVLAN Operation Pointer
  [1:0] POINTER — InterVLAN location pointer - This field points to the InterVLAN location that will be read/written by accesses to Enet_Pn_InterVLANx_A/B/C (the InterVLAN locations are accessed by a maibox). Valid pointer locations are 1 to x (where x is the number of locations - pointer location zero is unused). For example, if configured with 2 intervlan routes then only the values of 1 and 2 are valid.
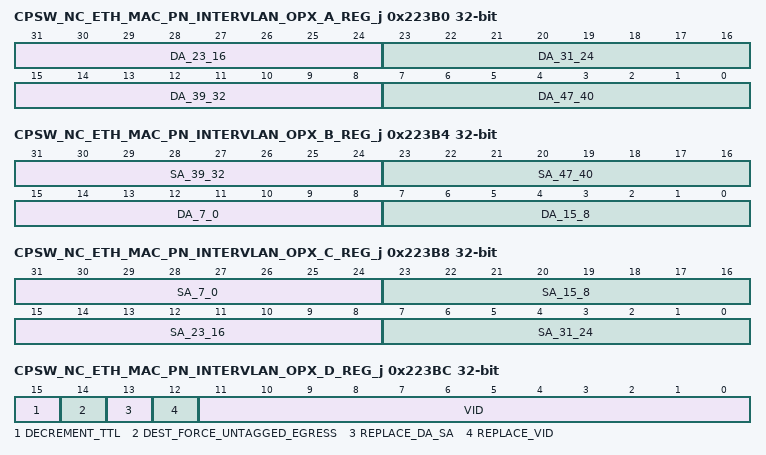
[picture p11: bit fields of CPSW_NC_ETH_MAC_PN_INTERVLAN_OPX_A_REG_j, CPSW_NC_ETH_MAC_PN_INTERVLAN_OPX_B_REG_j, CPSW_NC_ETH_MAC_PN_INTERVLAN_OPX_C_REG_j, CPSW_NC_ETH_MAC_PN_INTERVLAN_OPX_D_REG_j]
0x223B0 CPSW_NC_ETH_MAC_PN_INTERVLAN_OPX_A_REG_j — Enet Port N Tx Egress InterVLAN A
  [31:24] DA_23_16 — Destination Address bits 23:16
  [23:16] DA_31_24 — Destination Address bits 31:24
  [15:8] DA_39_32 — Destination Address bits 39:32
  [7:0] DA_47_40 — Destination Address bits 47:40
0x223B4 CPSW_NC_ETH_MAC_PN_INTERVLAN_OPX_B_REG_j — Enet Port N Tx Egress InterVLAN B
  [31:24] SA_39_32 — Source Address bits 39:32
  [23:16] SA_47_40 — Source Address bits 47:40
  [15:8] DA_7_0 — Destination Address bits 7:0
  [7:0] DA_15_8 — Destination Address bits 15:8
0x223B8 CPSW_NC_ETH_MAC_PN_INTERVLAN_OPX_C_REG_j — Enet Port N Tx Egress InterVLAN C
  [31:24] SA_7_0 — Source Address bits 7:0
  [23:16] SA_15_8 — Source Address bits 15:8
  [15:8] SA_23_16 — Source Address bits 23:16
  [7:0] SA_31_24 — Source Address bits 31:24
0x223BC CPSW_NC_ETH_MAC_PN_INTERVLAN_OPX_D_REG_j — Enet Port N Tx Egress InterVLAN D
  [15] DECREMENT_TTL — Decrement Time To Live - When set, the Time To Live (TTL) field in the header is decremented. IPV4 - Decrement the TTL byte and update the Header Checksum. IPV6 - Decrement the Hop Limit. note: When this bit is set, the ALE should be configured to send any IPv4/6 packet with a zero or one TTL field to the host with the ALE egress operation ttl_check bit.When this bit is cleared the TTL/Hop Limit fields are not checked or modified.
  [14] DEST_FORCE_UNTAGGED_EGRESS — Destination VLAN Force Untagged Egress - When set, this bit indicates that the VLAN should be removed on egress for the routed packet. The replace_vid bit should be set for this bit to be used, otherwise force untagged egress comes from the address lookup engine.
  [13] REPLACE_DA_SA — Replace Destination Address and Source Address - When set this bit indicates that the routed packet destination address should be replaced by da[47:0] and the source address should be replaced by sa[47:0].
  [12] REPLACE_VID — Replace VLAN ID - When set this bit indicates that the VLAN ID should be replaced for the routed packet.
  [11:0] VID — VLAN ID
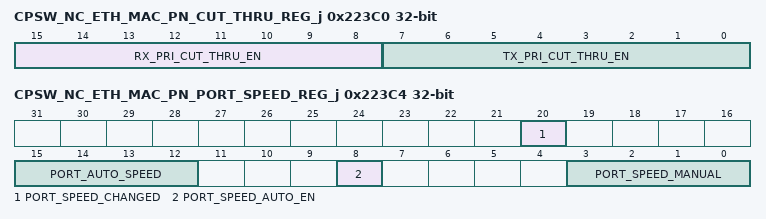
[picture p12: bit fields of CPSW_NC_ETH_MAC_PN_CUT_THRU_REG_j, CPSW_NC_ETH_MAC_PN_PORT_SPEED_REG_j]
0x223C0 CPSW_NC_ETH_MAC_PN_CUT_THRU_REG_j — Enet Port N Cut Thru Priority Enable
  [15:8] RX_PRI_CUT_THRU_EN — Receive Cut Thru Priority Enable
  [7:0] TX_PRI_CUT_THRU_EN — Transmit Cut Thru Priority Enable
0x223C4 CPSW_NC_ETH_MAC_PN_PORT_SPEED_REG_j access per field — Enet Port Speed
  [20] PORT_SPEED_CHANGED ro — Speed Changed - Status bit that when set indicates the automatically detected port speed dropped from 100Mbps to 10Mbps or dropped from 2.5G to 1G. This bit is cleared to zero when the auto_speed_en bit is cleared to zero.
  [15:12] PORT_AUTO_SPEED ro — Detected Auto Speed - This speed is the automatically detected port speed when auto_speed_en is set. This reflects the manual speed configuration when auto_speed_en is not set. If auto_speed_en is set, then this value transitions to a non-zero value when the hardware has finished the speed detection process.
  [8] PORT_SPEED_AUTO_EN rw — Automatic Speed Detection Enable 0 - The port speed is configured manually. 1 - The port automatically detects the port speed.
  [3:0] PORT_SPEED_MANUAL rw — Port Speed - This is the manual port speed that is written by software when auto_speed_en is not set. When auto_speed_en is zero and speed is zero the port is disabled for cut-thru operations. 0000 - Port speed disabled (not a port disable) 0001 - 10Mpbs 0010 - 100Mbps 0011 - 1G 0100 - 2.5G 0101 - 5G 0110 - 10G 0111 through 1111 Reserved
0x32000 CPSW_NC_EST_FETCH_LOC — The Revision Register contains the ID and revision information.
  [21:0] LOC — RAM Location
0x34000 CPSW_NC_CPDMA_REGS_FH_IDVER_REG ro reset 0x18010A — CPDMA FHost IDVER
  [31:0] FH_IDVER
0x34004 CPSW_NC_CPDMA_REGS_FH_CONTROL_REG — CPDMA FHost Control Register
  [0] FH_EN — FHost Enable 0 - Disabled 1 - Enabled
0x34008 CPSW_NC_CPDMA_REGS_FH_TEARDOWN_REG — CPDMA FHost Teardown Register
  [2:0] FH_TDN_CH — CPDMA FHost Teardown Channel - FHost channel teardown is commanded by writing the encoded value of the channel to be torn down. The teardown register is read as zero. 000 - teardown channel 0 ... 111 - teardown channel 7
0x3400C CPSW_NC_CPDMA_REGS_FH_CONTROL2_REG — CPDMA FHost Control Two Register
  [7:0] FH_EOQ_INT — FHost Interrupt on EOQ only - When set, a corresponding channel issues an FH_PEND[7:0] interrupt only on end of queue (EOQ). When clear, a corresponding channel issues an interrupt at every end of packet (EOP).
0x34010 CPSW_NC_CPDMA_REGS_TH_IDVER_REG ro reset 0x18010A — CPDMA THost IDVER
  [31:0] TH_IDVER
0x34014 CPSW_NC_CPDMA_REGS_TH_CONTROL_REG — CPDMA THost Control Register
  [0] TH_EN — THost DMA Enable 0 - Disabled 1 - Enabled
0x34018 CPSW_NC_CPDMA_REGS_TH_TEARDOWN_REG — CPDMA THost Teardown Register
  [2:0] TH_TDN_CH — THost Teardown Channel - THost channel teardown is commanded by writing the encoded value of the channel to be torn down. The teardown register is read as zero. 000 - teardown channel 0 ... 111 - teardown channel 7
0x3401C CPSW_NC_CPDMA_REGS_SOFT_RESET_REG — CPDMA Soft Reset Register
  [0] SOFT_RESET — Software reset - Writing a one to this bit causes the entire CPSW logic to be reset. Software reset occurs when the DMA Controllers are in an idle state to avoid locking up the VBUSP bus. After writing a one to this bit, it may be polled to determine if the reset has occurred. If a one is read, the reset has not yet occurred. If a zero is read then reset has occurred.
